# STM32WB30_CM4 register map
File version: 1.4-IAR
CPU: CM4 r0p1, little endian, MPU, FPU, 4 interrupt priority bits
Registers are 32-bit, read-write, reset 0x0 unless marked. A register's access mark holds for its fields unless they carry their own. Offsets are from the block's base; [hi:lo] are bit positions.

## Flash
Base 0x58004000
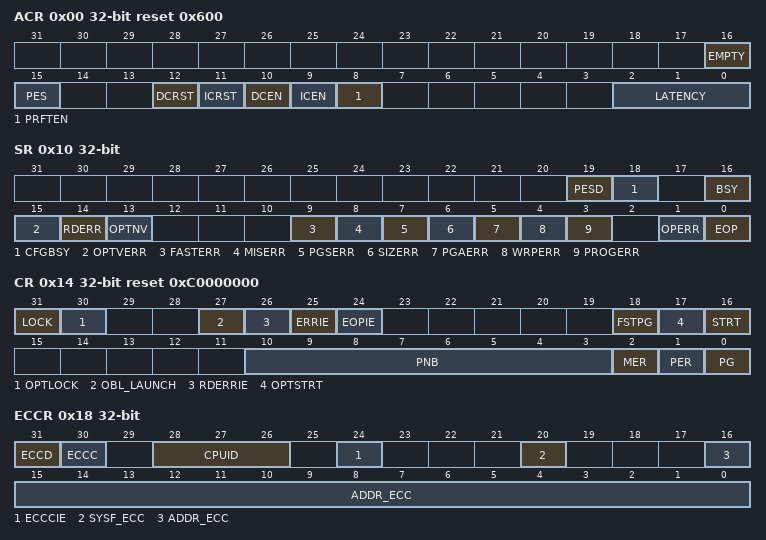
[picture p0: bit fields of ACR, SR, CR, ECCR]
0x00 ACR reset 0x600 — Access control register
  [16] EMPTY — Flash User area empty
  [15] PES — CPU1 CortexM4 program erase suspend request
  [12] DCRST — Data cache reset
  [11] ICRST — Instruction cache reset
  [10] DCEN — Data cache enable
  [9] ICEN — Instruction cache enable
  [8] PRFTEN — Prefetch enable
  [2:0] LATENCY
0x08 KEYR wo — Flash key register
0x0C OPTKEYR wo — Option byte key register
  [31:0] OPTKEYR — Option byte key
0x10 SR access per field — Status register
  [19] PESD ro — Programming or erase operation suspended
  [18] CFGBSY ro — Programming or erase configuration busy
  [16] BSY ro — Busy
  [15] OPTVERR rw — Option validity error
  [14] RDERR rw — PCROP read error
  [13] OPTNV ro — User Option OPTVAL indication
  [9] FASTERR rw — Fast programming error
  [8] MISERR rw — Fast programming data miss error
  [7] PGSERR rw — Programming sequence error
  [6] SIZERR rw — Size error
  [5] PGAERR rw — Programming alignment error
  [4] WRPERR rw — Write protected error
  [3] PROGERR rw — Programming error
  [1] OPERR rw — Operation error
  [0] EOP rw — End of operation
0x14 CR reset 0xC0000000 — Flash control register
  [31] LOCK — FLASH_CR Lock
  [30] OPTLOCK — Options Lock
  [27] OBL_LAUNCH — Force the option byte loading
  [26] RDERRIE — PCROP read error interrupt enable
  [25] ERRIE — Error interrupt enable
  [24] EOPIE — End of operation interrupt enable
  [18] FSTPG — Fast programming
  [17] OPTSTRT — Options modification start
  [16] STRT — Start
  [10:3] PNB — Page number selection
  [2] MER — This bit triggers the mass erase (all user pages) when set
  [1] PER — Page erase
  [0] PG — Programming
0x18 ECCR access per field — Flash ECC register
  [31] ECCD rw — ECC detection
  [30] ECCC rw — ECC correction
  [28:26] CPUID ro — CPU identification
  [24] ECCCIE rw — ECC correction interrupt enable
  [20] SYSF_ECC ro — System Flash ECC fail
  [16:0] ADDR_ECC ro — ECC fail address
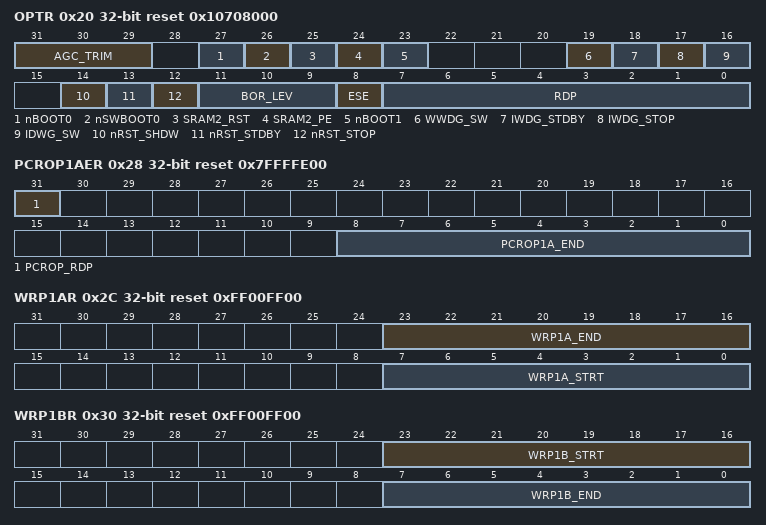
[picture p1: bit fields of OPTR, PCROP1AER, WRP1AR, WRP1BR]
0x20 OPTR reset 0x10708000 — Flash option register
  [31:29] AGC_TRIM — Radio Automatic Gain Control Trimming
  [27] nBOOT0 — nBoot0 option bit
  [26] nSWBOOT0 — Software Boot0
  [25] SRAM2_RST — SRAM2 Erase when system reset
  [24] SRAM2_PE — SRAM2 parity check enable
  [23] nBOOT1 — Boot configuration
  [19] WWDG_SW — Window watchdog selection
  [18] IWDG_STDBY — Independent watchdog counter freeze in Standby mode
  [17] IWDG_STOP — Independent watchdog counter freeze in Stop mode
  [16] IDWG_SW — Independent watchdog selection
  [14] nRST_SHDW
  [13] nRST_STDBY
  [12] nRST_STOP
  [11:9] BOR_LEV — BOR reset Level
  [8] ESE — Security enabled
  [7:0] RDP — Read protection level
0x24 PCROP1ASR reset 0xFFFFFE00 — Flash Bank 1 PCROP Start address zone A register
  [8:0] PCROP1A_STRT — Bank 1 PCROPQ area start offset
0x28 PCROP1AER reset 0x7FFFFE00 — Flash Bank 1 PCROP End address zone A register
  [31] PCROP_RDP — PCROP area preserved when RDP level decreased
  [8:0] PCROP1A_END — Bank 1 PCROP area end offset
0x2C WRP1AR reset 0xFF00FF00 — Flash Bank 1 WRP area A address register
  [23:16] WRP1A_END — Bank 1 WRP first area A end offset
  [7:0] WRP1A_STRT — Bank 1 WRP first area A start offset
0x30 WRP1BR reset 0xFF00FF00 — Flash Bank 1 WRP area B address register
  [23:16] WRP1B_STRT — Bank 1 WRP second area B end offset
  [7:0] WRP1B_END — Bank 1 WRP second area B start offset
0x34 PCROP1BSR reset 0xFFFFFE00 — Flash Bank 1 PCROP Start address area B register
  [8:0] PCROP1B_STRT — Bank 1 PCROP area B start offset
0x38 PCROP1BER reset 0xFFFFFE00 — Flash Bank 1 PCROP End address area B register
  [8:0] PCROP1B_END — Bank 1 PCROP area end area B offset
0x3C IPCCBR reset 0xFFFFC000 — IPCC mailbox data buffer address register
  [13:0] IPCCDBA — PCC mailbox data buffer base address
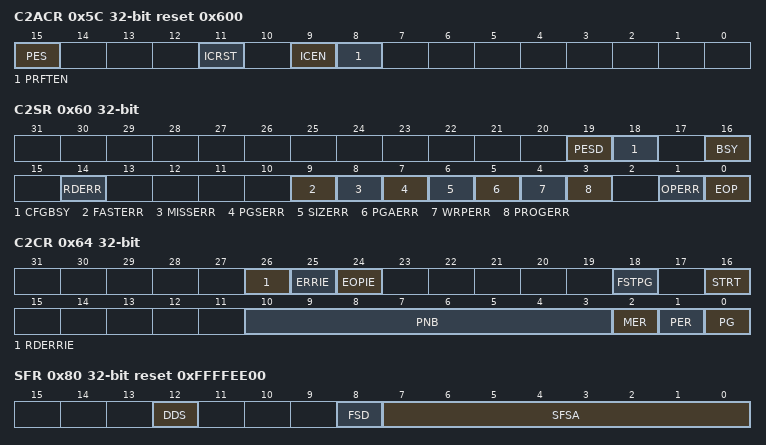
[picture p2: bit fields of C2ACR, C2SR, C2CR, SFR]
0x5C C2ACR reset 0x600 — CPU2 cortex M0 access control register
  [15] PES — CPU2 cortex M0 program erase suspend request
  [11] ICRST — CPU2 cortex M0 instruction cache reset
  [9] ICEN — CPU2 cortex M0 instruction cache enable
  [8] PRFTEN — CPU2 cortex M0 prefetch enable
0x60 C2SR — CPU2 cortex M0 status register
  [19] PESD — Programming or erase operation suspended
  [18] CFGBSY — Programming or erase configuration busy
  [16] BSY — Busy
  [14] RDERR — PCROP read error
  [9] FASTERR — Fast programming error
  [8] MISSERR — Fast programming data miss error
  [7] PGSERR — Programming sequence error
  [6] SIZERR — Size error
  [5] PGAERR — Programming alignment error
  [4] WRPERR — write protection error
  [3] PROGERR — Programming error
  [1] OPERR — Operation error
  [0] EOP — End of operation
0x64 C2CR — CPU2 cortex M0 control register
  [26] RDERRIE — PCROP read error interrupt enable
  [25] ERRIE — Error interrupt enable
  [24] EOPIE — End of operation interrupt enable
  [18] FSTPG — Fast programming
  [16] STRT — Start
  [10:3] PNB — Page Number selection
  [2] MER — Masse erase
  [1] PER — Page erase
  [0] PG — Programming
0x80 SFR reset 0xFFFFEE00 — Secure flash start address register
  [12] DDS — Disable Cortex M0 debug access
  [8] FSD — Flash security disable
  [7:0] SFSA — Secure flash start address
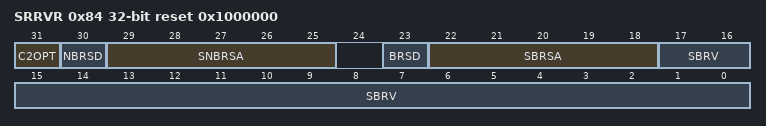
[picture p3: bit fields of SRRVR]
0x84 SRRVR reset 0x1000000 — Secure SRAM2 start address and cortex M0 reset vector register
  [31] C2OPT — CPU2 cortex M0 boot reset vector memory selection
  [30] NBRSD — non-backup SRAM2b security disable
  [29:25] SNBRSA — Secure non backup SRAM2a start address
  [23] BRSD — backup SRAM2a security disable
  [22:18] SBRSA — Secure backup SRAM2a start address
  [17:0] SBRV — cortex M0 access control register
